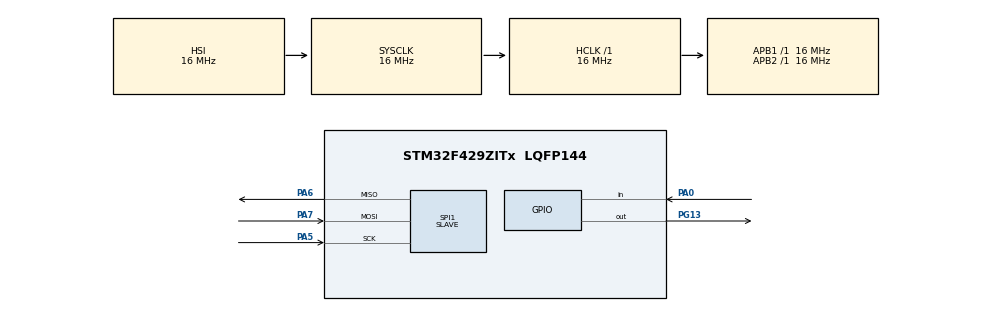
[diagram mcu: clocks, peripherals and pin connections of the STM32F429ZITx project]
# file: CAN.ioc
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Mcu.Family=STM32F4
Mcu.Name=STM32F429ZITx
Mcu.Package=LQFP144
NVIC.PriorityGroup=NVIC_PRIORITYGROUP_4
NVIC.SPI1_IRQn=true\:0\:0\:false\:false\:true\:true\:true
PA0/WKUP.Signal=GPIO_Input
PA13.Mode=Serial_Wire
PA13.Signal=SYS_JTMS-SWDIO
PA14.Mode=Serial_Wire
PA14.Signal=SYS_JTCK-SWCLK
PA5.Mode=Full_Duplex_Slave
PA5.Signal=SPI1_SCK
PA6.Mode=Full_Duplex_Slave
PA6.Signal=SPI1_MISO
PA7.Mode=Full_Duplex_Slave
PA7.Signal=SPI1_MOSI
PG13.Signal=GPIO_Output
ProjectManager.HeapSize=0x200
ProjectManager.StackSize=0x400
ProjectManager.TargetToolchain=MDK-ARM V5
RCC.AHBFreq_Value=16000000
RCC.APB1Freq_Value=16000000
RCC.APB1TimFreq_Value=16000000
RCC.APB2Freq_Value=16000000
RCC.APB2TimFreq_Value=16000000
RCC.CortexFreq_Value=16000000
RCC.HCLKFreq_Value=16000000
RCC.HSE_VALUE=25000000
RCC.HSI_VALUE=16000000
RCC.LSE_VALUE=32768
RCC.SYSCLKFreq_VALUE=16000000
RCC.VCOOutputFreq_Value=192000000
SPI1.Direction=SPI_DIRECTION_2LINES
SPI1.Mode=SPI_MODE_SLAVE
SPI1.VirtualType=VM_SLAVE
board=custom

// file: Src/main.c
/* USER CODE BEGIN Header */
/**
  ******************************************************************************
  * @file           : main.c
  * @brief          : Main program body
  ******************************************************************************
  * @attention
  *
  * <h2><center>&copy; Copyright (c) 2019 STMicroelectronics.
  * All rights reserved.</center></h2>
  *
  * This software component is licensed by ST under BSD 3-Clause license,
  * the "License"; You may not use this file except in compliance with the
  * License. You may obtain a copy of the License at:
  *                        opensource.org/licenses/BSD-3-Clause
  *
  ******************************************************************************
  */
/* USER CODE END Header */

#include "main.h"

SPI_HandleTypeDef hspi1;

/* USER CODE BEGIN PV */
uint8_t strReceive[14] = {0};
int SPI_flag = 0;
int flag = 0;
/* USER CODE END PV */

void SystemClock_Config(void);
static void MX_GPIO_Init(void);
static void MX_SPI1_Init(void);

/* USER CODE BEGIN 0 */
void HAL_SPI_RxCpltCallback(SPI_HandleTypeDef *hspi)
{
	if (hspi == &hspi1)
	{
		if (hspi1.RxXferCount == 0)
		{
			SPI_flag = 1;
		}
	}
}
/* USER CODE END 0 */

int main(void)
{

  /* MCU Configuration--------------------------------------------------------*/

  /* Reset of all peripherals, Initializes the Flash interface and the Systick. */
  HAL_Init();

  /* Configure the system clock */
  SystemClock_Config();

  /* Initialize all configured peripherals */
  MX_GPIO_Init();
  MX_SPI1_Init();

  /* Infinite loop */
  /* USER CODE BEGIN WHILE */
  while (1)
  {
		//HAL_USART_Receive(&husart2, strReceive, 14, 1500);
		//HAL_USART_Receive_IT(&husart2, strReceive, 14);
		HAL_SPI_Receive_IT(&hspi1, strReceive, 14);
		//HAL_USART_Receive_IT(&husart2, strReceive, 14);
		//HAL_USART_Receive(&husart1, strReceive, 14, 1500);
		if (SPI_flag == 1)
		{
			HAL_GPIO_TogglePin(GPIOG, GPIO_PIN_13);
			HAL_Delay(2000);
			HAL_GPIO_TogglePin(GPIOG, GPIO_PIN_13);
			//CAN1_Tx();
			SPI_flag = 0;
		}
		/*if (HAL_GPIO_ReadPin(GPIOA, GPIO_PIN_0) == 1)
		{
			HAL_Delay(500);
			if (HAL_GPIO_ReadPin(GPIOA, GPIO_PIN_0) == 0)
			{
				CAN1_Tx();
			}
		}
		if (flag == 1)
		{
			HAL_GPIO_TogglePin(GPIOG, GPIO_PIN_13);
			HAL_Delay(2000);
			HAL_GPIO_TogglePin(GPIOG, GPIO_PIN_13);
			flag = 0;
		}*/
		HAL_Delay(100);
    /* USER CODE END WHILE */

  }
}

void SystemClock_Config(void)
{
  RCC_OscInitTypeDef RCC_OscInitStruct = {0};
  RCC_ClkInitTypeDef RCC_ClkInitStruct = {0};

  /** Configure the main internal regulator output voltage
  */
  __HAL_RCC_PWR_CLK_ENABLE();
  __HAL_PWR_VOLTAGESCALING_CONFIG(PWR_REGULATOR_VOLTAGE_SCALE3);
  /** Initializes the CPU, AHB and APB busses clocks
  */
  RCC_OscInitStruct.OscillatorType = RCC_OSCILLATORTYPE_HSI;
  RCC_OscInitStruct.HSIState = RCC_HSI_ON;
  RCC_OscInitStruct.HSICalibrationValue = RCC_HSICALIBRATION_DEFAULT;
  RCC_OscInitStruct.PLL.PLLState = RCC_PLL_NONE;
  if (HAL_RCC_OscConfig(&RCC_OscInitStruct) != HAL_OK)
  {
    Error_Handler();
  }
  /** Initializes the CPU, AHB and APB busses clocks
  */
  RCC_ClkInitStruct.ClockType = RCC_CLOCKTYPE_HCLK|RCC_CLOCKTYPE_SYSCLK
                              |RCC_CLOCKTYPE_PCLK1|RCC_CLOCKTYPE_PCLK2;
  RCC_ClkInitStruct.SYSCLKSource = RCC_SYSCLKSOURCE_HSI;
  RCC_ClkInitStruct.AHBCLKDivider = RCC_SYSCLK_DIV1;
  RCC_ClkInitStruct.APB1CLKDivider = RCC_HCLK_DIV1;
  RCC_ClkInitStruct.APB2CLKDivider = RCC_HCLK_DIV1;

  if (HAL_RCC_ClockConfig(&RCC_ClkInitStruct, FLASH_LATENCY_0) != HAL_OK)
  {
    Error_Handler();
  }
}

static void MX_SPI1_Init(void)
{

  /* SPI1 parameter configuration*/
  hspi1.Instance = SPI1;
  hspi1.Init.Mode = SPI_MODE_SLAVE;
  hspi1.Init.Direction = SPI_DIRECTION_2LINES;
  hspi1.Init.DataSize = SPI_DATASIZE_8BIT;
  hspi1.Init.CLKPolarity = SPI_POLARITY_LOW;
  hspi1.Init.CLKPhase = SPI_PHASE_1EDGE;
  hspi1.Init.NSS = SPI_NSS_SOFT;
  hspi1.Init.FirstBit = SPI_FIRSTBIT_MSB;
  hspi1.Init.TIMode = SPI_TIMODE_DISABLE;
  hspi1.Init.CRCCalculation = SPI_CRCCALCULATION_DISABLE;
  hspi1.Init.CRCPolynomial = 10;
  if (HAL_SPI_Init(&hspi1) != HAL_OK)
  {
    Error_Handler();
  }

}

static void MX_GPIO_Init(void)
{
  GPIO_InitTypeDef GPIO_InitStruct = {0};

  /* GPIO Ports Clock Enable */
  __HAL_RCC_GPIOA_CLK_ENABLE();
  __HAL_RCC_GPIOG_CLK_ENABLE();

  /*Configure GPIO pin Output Level */
  HAL_GPIO_WritePin(GPIOG, GPIO_PIN_13, GPIO_PIN_RESET);

  /*Configure GPIO pin : PA0 */
  GPIO_InitStruct.Pin = GPIO_PIN_0;
  GPIO_InitStruct.Mode = GPIO_MODE_INPUT;
  GPIO_InitStruct.Pull = GPIO_NOPULL;
  HAL_GPIO_Init(GPIOA, &GPIO_InitStruct);

  /*Configure GPIO pin : PG13 */
  GPIO_InitStruct.Pin = GPIO_PIN_13;
  GPIO_InitStruct.Mode = GPIO_MODE_OUTPUT_PP;
  GPIO_InitStruct.Pull = GPIO_NOPULL;
  GPIO_InitStruct.Speed = GPIO_SPEED_FREQ_LOW;
  HAL_GPIO_Init(GPIOG, &GPIO_InitStruct);

}

void Error_Handler(void)
{
}

/************************ (C) COPYRIGHT STMicroelectronics *****END OF FILE****/
